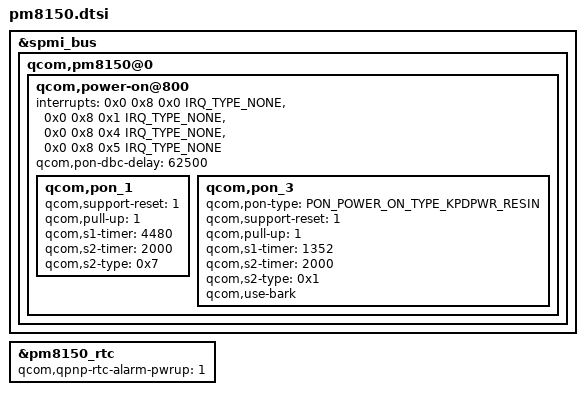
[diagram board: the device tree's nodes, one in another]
&spmi_bus {
	qcom,pm8150@0 {
		qcom,power-on@800 {
			interrupts = <0x0 0x8 0x0 IRQ_TYPE_NONE>,
				   <0x0 0x8 0x1 IRQ_TYPE_NONE>,
				   <0x0 0x8 0x4 IRQ_TYPE_NONE>,
				   <0x0 0x8 0x5 IRQ_TYPE_NONE>;
			interrupt-names = "kpdpwr", "resin",
					"resin-bark", "kpdpwr-resin-bark";
			qcom,pon-dbc-delay = <62500>;

			qcom,pon_1 {
				qcom,support-reset = <1>;
				qcom,pull-up = <1>;
				qcom,s1-timer = <4480>;
				qcom,s2-timer = <2000>;
				qcom,s2-type = <0x7>;
			};

			qcom,pon_3 {
				qcom,pon-type = <PON_POWER_ON_TYPE_KPDPWR_RESIN>;
				qcom,support-reset = <1>;
				qcom,pull-up = <1>;
				qcom,s1-timer = <1352>;
				qcom,s2-timer = <2000>;
				qcom,s2-type = <0x1>;
				qcom,use-bark;
			};
		};
	};
};

&pm8150_rtc {
	qcom,qpnp-rtc-alarm-pwrup = <1>;
};
